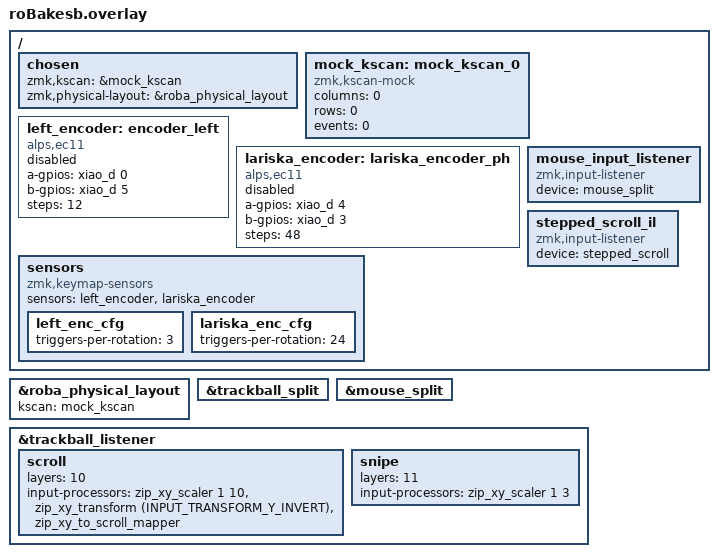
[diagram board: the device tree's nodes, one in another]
#include "roBa_matrix.dtsi"
#include "roBakesb_addr.dtsi"
#include "roBakesb_lariska_transform.dtsi"
#include <input/processors.dtsi>
#include <dt-bindings/zmk/input_transform.h>

/ {
    chosen {
        zmk,kscan = &mock_kscan;
        zmk,physical-layout = &roba_physical_layout;
    };

    mock_kscan: mock_kscan_0 {
        compatible = "zmk,kscan-mock";
        columns = <0>;
        rows = <0>;
        events = <0>;
    };

    /* Placeholder encoder at slot 0 so lariska_encoder lands at slot 1.
     * Events for slot 0 come from the left keyboard peripheral (real ec11). */
    left_encoder: encoder_left {
        compatible = "alps,ec11";
        a-gpios = <&xiao_d 0 (GPIO_ACTIVE_HIGH | GPIO_PULL_UP)>;
        b-gpios = <&xiao_d 5 (GPIO_ACTIVE_HIGH | GPIO_PULL_UP)>;
        steps = <12>;
        status = "disabled";
    };

    /* Placeholder encoder at slot 1; real events come from lariska QDEC. */
    lariska_encoder: lariska_encoder_ph {
        compatible = "alps,ec11";
        a-gpios = <&xiao_d 4 (GPIO_ACTIVE_HIGH | GPIO_PULL_UP)>;
        b-gpios = <&xiao_d 3 (GPIO_ACTIVE_HIGH | GPIO_PULL_UP)>;
        steps = <48>;
        status = "disabled";
    };

    sensors: sensors {
        compatible = "zmk,keymap-sensors";
        sensors = <&left_encoder &lariska_encoder>;
        left_enc_cfg: left_enc_cfg {
            /* This encoder yields 4 pulses (4 * 30 = 120 deg) per detent, so
             * trigger_degrees must be 120 -> 360/120 = 3 for exactly one tick
             * per detent with zero remainder. (tpr=4 gave trigger_degrees=90, a
             * 30-deg remainder that drifted to a double every 3rd detent: the
             * observed "1, 1, 2".) */
            triggers-per-rotation = <3>;
        };
        lariska_enc_cfg: lariska_enc_cfg {
            triggers-per-rotation = <24>;
        };
    };

    mouse_input_listener: mouse_input_listener {
        compatible = "zmk,input-listener";
        status = "okay";
        device = <&mouse_split>;
    };

    /* Routes stepped_scroll events (one REL_WHEEL tick per detent) to HID. */
    stepped_scroll_il: stepped_scroll_il {
        compatible = "zmk,input-listener";
        device = <&stepped_scroll>;
    };
};

&roba_physical_layout {
    kscan = <&mock_kscan>;
};

&trackball_split {
    status = "okay";
};

&mouse_split {
    status = "okay";
};

&trackball_listener {
    status = "okay";

    scroll {
        layers = <10>;
        input-processors = <&zip_xy_scaler 1 10>, <&zip_xy_transform (INPUT_TRANSFORM_Y_INVERT)>, <&zip_xy_to_scroll_mapper>;
    };

    snipe {
        layers = <11>;
        input-processors = <&zip_xy_scaler 1 3>;
    };
};

/* nice_nano already defines zephyr_udc0: &usbd { status = "okay" } in its
 * base DTS, so no explicit USB enable is needed here. */
